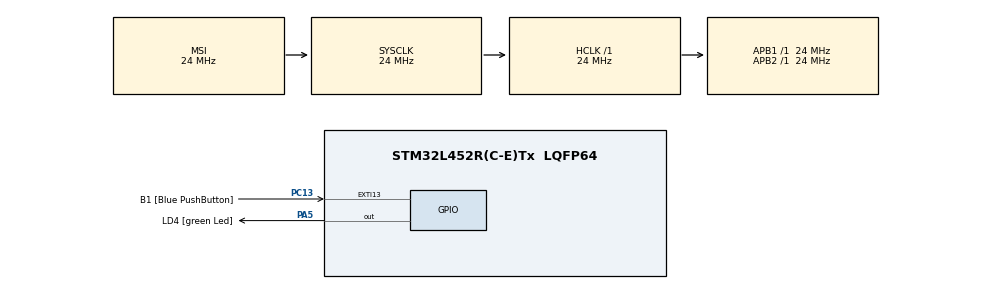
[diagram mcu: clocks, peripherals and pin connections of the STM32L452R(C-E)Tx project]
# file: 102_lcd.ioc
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FREERTOS.Tasks01=defaultTask,24,256,StartDefaultTask,Default,NULL,Dynamic,NULL,NULL
FREERTOS.configMINIMAL_STACK_SIZE=256
FREERTOS.configUSE_NEWLIB_REENTRANT=1
FREERTOS.configUSE_TICKLESS_IDLE=1
Mcu.Family=STM32L4
Mcu.Name=STM32L452R(C-E)Tx
Mcu.Package=LQFP64
NVIC.PriorityGroup=NVIC_PRIORITYGROUP_4
NVIC.RTC_WKUP_IRQn=true\:5\:0\:false\:false\:true\:true\:true\:true\:true
NVIC.TIM6_DAC_IRQn=true\:15\:0\:false\:false\:true\:false\:false\:true\:true
NVIC.TimeBase=TIM6_DAC_IRQn
NVIC.TimeBaseIP=TIM6
PA13\ (JTMS/SWDIO).GPIO_Label=TMS
PA13\ (JTMS/SWDIO).Mode=Serial_Wire
PA13\ (JTMS/SWDIO).Signal=SYS_JTMS-SWDIO
PA14\ (JTCK/SWCLK).GPIO_Label=TCK
PA14\ (JTCK/SWCLK).Mode=Serial_Wire
PA14\ (JTCK/SWCLK).Signal=SYS_JTCK-SWCLK
PA2.GPIO_Label=USART_TX
PA2.GPIO_Mode=GPIO_MODE_AF_PP
PA2.GPIO_PuPd=GPIO_NOPULL
PA2.GPIO_Speed=GPIO_SPEED_FREQ_VERY_HIGH
PA2.Signal=USART2_TX
PA3.GPIO_Label=USART_RX
PA3.GPIO_Mode=GPIO_MODE_AF_PP
PA3.GPIO_PuPd=GPIO_NOPULL
PA3.GPIO_Speed=GPIO_SPEED_FREQ_VERY_HIGH
PA3.Signal=USART2_RX
PA5.GPIO_Label=LD4 [green Led]
PA5.GPIO_ModeDefaultOutputPP=GPIO_MODE_OUTPUT_PP
PA5.GPIO_PuPd=GPIO_NOPULL
PA5.GPIO_Speed=GPIO_SPEED_FREQ_LOW
PA5.Signal=GPIO_Output
PB3\ (JTDO/TRACESWO).GPIO_Label=SWO
PB3\ (JTDO/TRACESWO).Signal=SYS_JTDO-SWO
PC13.GPIO_Label=B1 [Blue PushButton]
PC13.GPIO_ModeDefaultEXTI=GPIO_MODE_IT_FALLING
PC13.GPIO_PuPd=GPIO_NOPULL
PC13.Signal=GPXTI13
PC14-OSC32_IN\ (PC14).Mode=LSE-External-Oscillator
PC14-OSC32_IN\ (PC14).Signal=RCC_OSC32_IN
PC15-OSC32_OUT\ (PC15).Mode=LSE-External-Oscillator
PC15-OSC32_OUT\ (PC15).Signal=RCC_OSC32_OUT
PH0-OSC_IN\ (PH0).Signal=RCC_OSC_IN
PH1-OSC_OUT\ (PH1).Signal=RCC_OSC_OUT
ProjectManager.HeapSize=0x200
ProjectManager.StackSize=0x400
ProjectManager.TargetToolchain=STM32CubeIDE
RCC.ADCFreq_Value=96000000
RCC.AHBFreq_Value=24000000
RCC.APB1Freq_Value=24000000
RCC.APB1TimFreq_Value=24000000
RCC.APB2Freq_Value=24000000
RCC.APB2TimFreq_Value=24000000
RCC.CortexFreq_Value=24000000
RCC.HCLKFreq_Value=24000000
RCC.HSE_VALUE=8000000
RCC.HSI48_VALUE=48000000
RCC.HSI_VALUE=16000000
RCC.MSIClockRange=RCC_MSIRANGE_9
RCC.MSI_VALUE=24000000
RCC.PLLN=10
RCC.PREFETCH_ENABLE=1
RCC.RTCClockSelection=RCC_RTCCLKSOURCE_LSE
RCC.SYSCLKFreq_VALUE=24000000
RCC.USBFreq_Value=96000000
RCC.VCOOutputFreq_Value=240000000
VP_FREERTOS_VS_CMSIS_V2.Mode=CMSIS_V2
VP_RTC_VS_RTC_Activate.Mode=RTC_Enabled
VP_RTC_VS_RTC_WakeUp_intern.Mode=WakeUp
VP_SYS_VS_tim6.Mode=TIM6
board=NUCLEO-L452RE

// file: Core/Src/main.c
/* USER CODE BEGIN Header */
/*
 * Este proyecto es para hacer pruebas del FreeRTOS tickless mode en stop
 * mode 2 (en stop mode 2 para STM32L452 LPTIM 2 se apaga), se usa el RTC como
 * fuente de interrupcion de wakeup.
 *
 * Se usan dos delay en la unica tarea creada:
 *
 * Un hal_delay, que mantiene encendido un led mientras se ejecuta, para este
 * caso si todo funciona bien nunca se debería entrar en task idle, es
 * importante comprobar esto porque hay mucho bug dando vuelta y no confío.
 *
 * Un osDelay, aqui se entra en idle task de ahi al modo de bajo consumo
 * seleccionado, se usa el RTC para despertar. Aqui se debe cumplir que el
 * el tiempo que se manda a dormir sea menor al tiempo restante en idle.
 * Para el caso donde se usaba el LPTIM para tiempos de idle alto el
 * contador desbordaba y volvía a entrar, usando el RTC no se deberían
 * tener estos problema. Hay que estudiar bien el funcionamiento para no tener
 * dudas.
 *
 *
 *
 * Modificaciones que hay que hacer para que funcione:
 *
 * - En freeRTOSConfig.h, la macro configPRE_SLEEP_PROCESSING hay que eliminar
 * la sentencia x = 0, notar que este cambio no es persistente al ejecutar
 * CubeMX  Generate Code. Se debe volver a eliminar esta linea si se ejecuta
 * CubeMX.
 * - En port.c hay que comentar la instruccion:
 * //portNVIC_SYSTICK_CTRL_REG |= portNVIC_SYSTICK_ENABLE_BIT;
 * Al igual que antes este cambio no es persistente si se hace Generate Code
 * - En el MX para el RTC -> Wakeup -> Internal Wakeup luego en NVIC hay que
 * seleccionar RTC wake-up Interrupt throught EXT1 line 20, esto habilita
 * la interrupcion, debo investigar mejor como funciona.
 *
 * - Demas codigo en freertos.c, si es presevado luego de un Code Generator:
 * extern RTC_HandleTypeDef hrtc;
 * Codigo en pre y post sleep processing, calcular el tiempo en ms que el micro
 * debe dormir, preparar al RTC para que despierte al sistema, detener ticks
 * ir a dormir, reanudar ticks....
 *
 * Esta solucion tiene como ventaja que se deja libre el LPTIM 1, ademas que
 * se puede usar el LPTIM 2 de cambiar stop 2 por stop 1.
 * La solucion de usar LPTIM 1 como fuente de systick, en lugar de TIM6, es
 * superior, no tiene drift, el problema es que solo nos dejaría con LPTIM 2
 * en stop mode 1, stop mode 2 no representa un gran ahorro.
 * Las versiones de FreeRTOS tickless no tienen implementación oficial, esta
 * solucion que si es parte de una solucion oficial tiene bugs, el del macro
 * que hace tiempo esperado igual a 0.
 *
 */
/* USER CODE END Header */
#include "main.h"
#include "cmsis_os.h"

RTC_HandleTypeDef hrtc;

/* Definitions for defaultTask */
osThreadId_t defaultTaskHandle;
const osThreadAttr_t defaultTask_attributes =
{
    .name = "defaultTask",
    .stack_size = 256 * 4,
    .priority = (osPriority_t) osPriorityNormal,
};

void SystemClock_Config(void);
static void MX_GPIO_Init(void);
static void MX_RTC_Init(void);
void StartDefaultTask(void *argument);

int main(void)
{

    /* MCU Configuration--------------------------------------------------------*/

    /* Reset of all peripherals, Initializes the Flash interface and the Systick. */
    HAL_Init();

    /* Configure the system clock */
    SystemClock_Config();

    /* Initialize all configured peripherals */
    MX_GPIO_Init();
    MX_RTC_Init();

    /* Init scheduler */
    osKernelInitialize();

    /* Create the thread(s) */
    /* creation of defaultTask */
    defaultTaskHandle = osThreadNew(StartDefaultTask, NULL,
    &defaultTask_attributes);

    /* Start scheduler */
    osKernelStart();
    /* We should never get here as control is now taken by the scheduler */
    /* Infinite loop */
    while (1)
    {

    }
}

void SystemClock_Config(void)
{
    RCC_OscInitTypeDef RCC_OscInitStruct =
    {
        0
    };
    RCC_ClkInitTypeDef RCC_ClkInitStruct =
    {
        0
    };

    /** Configure the main internal regulator output voltage
     */
    if (HAL_PWREx_ControlVoltageScaling(PWR_REGULATOR_VOLTAGE_SCALE1) != HAL_OK)
    {
        Error_Handler();
    }

    /** Configure LSE Drive Capability
     */
    HAL_PWR_EnableBkUpAccess();
    __HAL_RCC_LSEDRIVE_CONFIG(RCC_LSEDRIVE_LOW);

    /** Initializes the RCC Oscillators according to the specified parameters
     * in the RCC_OscInitTypeDef structure.
     */
    RCC_OscInitStruct.OscillatorType = RCC_OSCILLATORTYPE_LSE
    | RCC_OSCILLATORTYPE_MSI;
    RCC_OscInitStruct.LSEState = RCC_LSE_ON;
    RCC_OscInitStruct.MSIState = RCC_MSI_ON;
    RCC_OscInitStruct.MSICalibrationValue = 0;
    RCC_OscInitStruct.MSIClockRange = RCC_MSIRANGE_9;
    RCC_OscInitStruct.PLL.PLLState = RCC_PLL_NONE;
    if (HAL_RCC_OscConfig(&RCC_OscInitStruct) != HAL_OK)
    {
        Error_Handler();
    }

    /** Initializes the CPU, AHB and APB buses clocks
     */
    RCC_ClkInitStruct.ClockType = RCC_CLOCKTYPE_HCLK | RCC_CLOCKTYPE_SYSCLK
    | RCC_CLOCKTYPE_PCLK1 | RCC_CLOCKTYPE_PCLK2;
    RCC_ClkInitStruct.SYSCLKSource = RCC_SYSCLKSOURCE_MSI;
    RCC_ClkInitStruct.AHBCLKDivider = RCC_SYSCLK_DIV1;
    RCC_ClkInitStruct.APB1CLKDivider = RCC_HCLK_DIV1;
    RCC_ClkInitStruct.APB2CLKDivider = RCC_HCLK_DIV1;

    if (HAL_RCC_ClockConfig(&RCC_ClkInitStruct, FLASH_LATENCY_1) != HAL_OK)
    {
        Error_Handler();
    }

    /** Enable MSI Auto calibration
     */
    HAL_RCCEx_EnableMSIPLLMode();
}

static void MX_RTC_Init(void)
{

    /** Initialize RTC Only
     */
    hrtc.Instance = RTC;
    hrtc.Init.HourFormat = RTC_HOURFORMAT_24;
    hrtc.Init.AsynchPrediv = 127;
    hrtc.Init.SynchPrediv = 255;
    hrtc.Init.OutPut = RTC_OUTPUT_DISABLE;
    hrtc.Init.OutPutRemap = RTC_OUTPUT_REMAP_NONE;
    hrtc.Init.OutPutPolarity = RTC_OUTPUT_POLARITY_HIGH;
    hrtc.Init.OutPutType = RTC_OUTPUT_TYPE_OPENDRAIN;
    if (HAL_RTC_Init(&hrtc) != HAL_OK)
    {
        Error_Handler();
    }

    /** Enable the WakeUp
     */
    if (HAL_RTCEx_SetWakeUpTimer_IT(&hrtc, 0, RTC_WAKEUPCLOCK_RTCCLK_DIV16)
    != HAL_OK)
    {
        Error_Handler();
    }

}

static void MX_GPIO_Init(void)
{
    GPIO_InitTypeDef GPIO_InitStruct =
    {
        0
    };

    /* GPIO Ports Clock Enable */
    __HAL_RCC_GPIOC_CLK_ENABLE();
    __HAL_RCC_GPIOH_CLK_ENABLE();
    __HAL_RCC_GPIOA_CLK_ENABLE();
    __HAL_RCC_GPIOB_CLK_ENABLE();

    /*Configure GPIO pin Output Level */
    HAL_GPIO_WritePin(LD4_GPIO_Port, LD4_Pin, GPIO_PIN_RESET);

    /*Configure GPIO pin : B1_Pin */
    GPIO_InitStruct.Pin = B1_Pin;
    GPIO_InitStruct.Mode = GPIO_MODE_IT_FALLING;
    GPIO_InitStruct.Pull = GPIO_NOPULL;
    HAL_GPIO_Init(B1_GPIO_Port, &GPIO_InitStruct);

    /*Configure GPIO pins : USART_TX_Pin USART_RX_Pin */
    GPIO_InitStruct.Pin = USART_TX_Pin | USART_RX_Pin;
    GPIO_InitStruct.Mode = GPIO_MODE_AF_PP;
    GPIO_InitStruct.Pull = GPIO_NOPULL;
    GPIO_InitStruct.Speed = GPIO_SPEED_FREQ_VERY_HIGH;
    GPIO_InitStruct.Alternate = GPIO_AF7_USART2;
    HAL_GPIO_Init(GPIOA, &GPIO_InitStruct);

    /*Configure GPIO pin : LD4_Pin */
    GPIO_InitStruct.Pin = LD4_Pin;
    GPIO_InitStruct.Mode = GPIO_MODE_OUTPUT_PP;
    GPIO_InitStruct.Pull = GPIO_NOPULL;
    GPIO_InitStruct.Speed = GPIO_SPEED_FREQ_LOW;
    HAL_GPIO_Init(LD4_GPIO_Port, &GPIO_InitStruct);

}

void StartDefaultTask(void *argument)
{
    /* USER CODE BEGIN 5 */
    /* Infinite loop */
    for (;;)
    {
        HAL_GPIO_WritePin(LD4_GPIO_Port, LD4_Pin, GPIO_PIN_SET);
        HAL_Delay(1000);
        HAL_GPIO_WritePin(LD4_GPIO_Port, LD4_Pin, GPIO_PIN_RESET);
        osDelay(1000);
    }
    /* USER CODE END 5 */
}

void HAL_TIM_PeriodElapsedCallback(TIM_HandleTypeDef *htim)
{
    if (htim->Instance == TIM6)
    {
        HAL_IncTick();
    }
}

void Error_Handler(void)
{
    __disable_irq();
    while (1)
    {
    }
}

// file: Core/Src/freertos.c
/* USER CODE BEGIN Header */
/**
 ******************************************************************************
 * File Name          : freertos.c
 * Description        : Code for freertos applications
 ******************************************************************************
 * @attention
 *
 * Copyright (c) 2023 STMicroelectronics.
 * All rights reserved.
 *
 * This software is licensed under terms that can be found in the LICENSE file
 * in the root directory of this software component.
 * If no LICENSE file comes with this software, it is provided AS-IS.
 *
 ******************************************************************************
 */
/* USER CODE END Header */

#include "FreeRTOS.h"
#include "task.h"
#include "main.h"

/* USER CODE BEGIN Variables */
extern RTC_HandleTypeDef hrtc;

/* USER CODE END Variables */

/* USER CODE BEGIN PREPOSTSLEEP */
__weak void PreSleepProcessing(uint32_t ulExpectedIdleTime)
{
    /* place for user code */
    uint32_t delay_ms = ulExpectedIdleTime * 2048ul;

    delay_ms /= 1000;

    HAL_RTCEx_SetWakeUpTimer_IT(&hrtc, delay_ms, RTC_WAKEUPCLOCK_RTCCLK_DIV16);
    HAL_SuspendTick();

    __DSB();
    HAL_PWREx_EnterSTOP2Mode(PWR_STOPENTRY_WFI);
    __ISB();

}

__weak void PostSleepProcessing(uint32_t ulExpectedIdleTime)
{
    /* place for user code */
    HAL_RTCEx_DeactivateWakeUpTimer(&hrtc);
    HAL_ResumeTick();
}
/* USER CODE END PREPOSTSLEEP */
